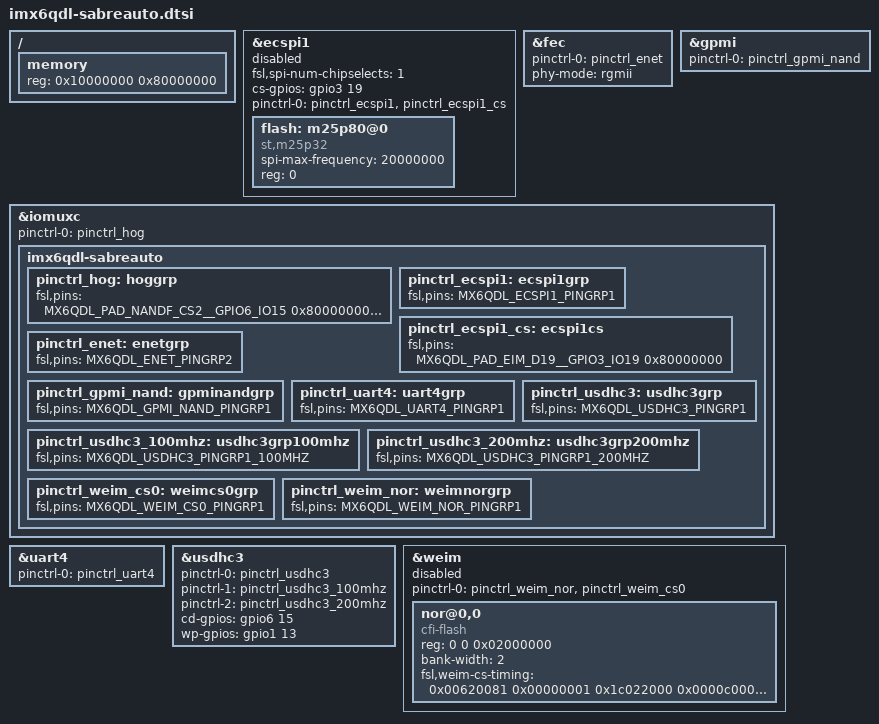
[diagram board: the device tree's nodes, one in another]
/*
 * Copyright 2012 Freescale Semiconductor, Inc.
 * Copyright 2011 Linaro Ltd.
 *
 * The code contained herein is licensed under the GNU General Public
 * License. You may obtain a copy of the GNU General Public License
 * Version 2 or later at the following locations:
 *
 * http://www.opensource.org/licenses/gpl-license.html
 * http://www.gnu.org/copyleft/gpl.html
 */

/ {
	memory {
		reg = <0x10000000 0x80000000>;
	};
};

&ecspi1 {
	fsl,spi-num-chipselects = <1>;
	cs-gpios = <&gpio3 19 0>;
	pinctrl-names = "default";
	pinctrl-0 = <&pinctrl_ecspi1 &pinctrl_ecspi1_cs>;
	status = "disabled"; /* pin conflict with WEIM NOR */

	flash: m25p80@0 {
		#address-cells = <1>;
		#size-cells = <1>;
		compatible = "st,m25p32";
		spi-max-frequency = <20000000>;
		reg = <0>;
	};
};

&fec {
	pinctrl-names = "default";
	pinctrl-0 = <&pinctrl_enet>;
	phy-mode = "rgmii";
	status = "okay";
};

&gpmi {
	pinctrl-names = "default";
	pinctrl-0 = <&pinctrl_gpmi_nand>;
	status = "okay";
};

&iomuxc {
	pinctrl-names = "default";
	pinctrl-0 = <&pinctrl_hog>;

	imx6qdl-sabreauto {
		pinctrl_hog: hoggrp {
			fsl,pins = <
				MX6QDL_PAD_NANDF_CS2__GPIO6_IO15 0x80000000
				MX6QDL_PAD_SD2_DAT2__GPIO1_IO13  0x80000000
				MX6QDL_PAD_GPIO_18__SD3_VSELECT 0x17059
			>;
		};

		pinctrl_ecspi1: ecspi1grp {
			fsl,pins = <MX6QDL_ECSPI1_PINGRP1>;
		};

		pinctrl_ecspi1_cs: ecspi1cs {
			fsl,pins = <
				MX6QDL_PAD_EIM_D19__GPIO3_IO19 0x80000000
			>;
		};

		pinctrl_enet: enetgrp {
			fsl,pins = <MX6QDL_ENET_PINGRP2>;
		};

		pinctrl_gpmi_nand: gpminandgrp {
			fsl,pins = <MX6QDL_GPMI_NAND_PINGRP1>;
		};

		pinctrl_uart4: uart4grp {
			fsl,pins = <MX6QDL_UART4_PINGRP1>;
		};

		pinctrl_usdhc3: usdhc3grp {
			fsl,pins = <MX6QDL_USDHC3_PINGRP1>;
		};

		pinctrl_usdhc3_100mhz: usdhc3grp100mhz {
			fsl,pins = <MX6QDL_USDHC3_PINGRP1_100MHZ>;
		};

		pinctrl_usdhc3_200mhz: usdhc3grp200mhz {
			fsl,pins = <MX6QDL_USDHC3_PINGRP1_200MHZ>;
		};

		pinctrl_weim_cs0: weimcs0grp {
			fsl,pins = <MX6QDL_WEIM_CS0_PINGRP1>;
		};

		pinctrl_weim_nor: weimnorgrp {
			fsl,pins = <MX6QDL_WEIM_NOR_PINGRP1>;
		};
	};
};

&uart4 {
	pinctrl-names = "default";
	pinctrl-0 = <&pinctrl_uart4>;
	status = "okay";
};

&usdhc3 {
	pinctrl-names = "default", "state_100mhz", "state_200mhz";
	pinctrl-0 = <&pinctrl_usdhc3>;
	pinctrl-1 = <&pinctrl_usdhc3_100mhz>;
	pinctrl-2 = <&pinctrl_usdhc3_200mhz>;
	cd-gpios = <&gpio6 15 0>;
	wp-gpios = <&gpio1 13 0>;
	status = "okay";
};

&weim {
	pinctrl-names = "default";
	pinctrl-0 = <&pinctrl_weim_nor &pinctrl_weim_cs0>;
	#address-cells = <2>;
	#size-cells = <1>;
	ranges = <0 0 0x08000000 0x08000000>;
	status = "disabled"; /* pin conflict with SPI NOR */

	nor@0,0 {
		compatible = "cfi-flash";
		reg = <0 0 0x02000000>;
		#address-cells = <1>;
		#size-cells = <1>;
		bank-width = <2>;
		fsl,weim-cs-timing = <0x00620081 0x00000001 0x1c022000
				0x0000c000 0x1404a38e 0x00000000>;
	};
};
